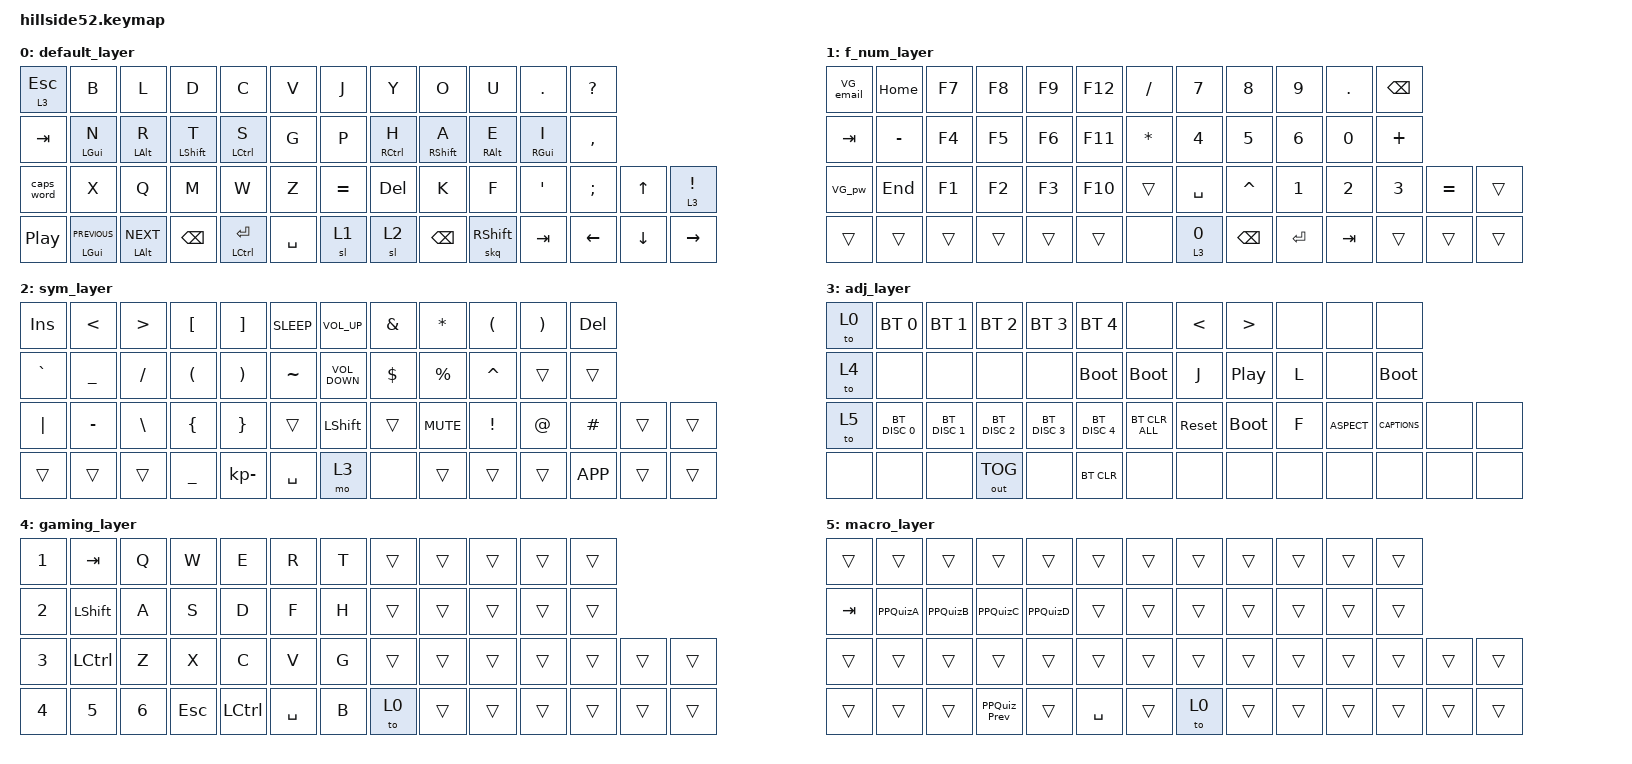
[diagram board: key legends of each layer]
/*
 * Copyright (c) 2021-2022 The ZMK Contributors
 *
 * SPDX-License-Identifier: MIT
 */

#include <behaviors.dtsi>
#include <dt-bindings/zmk/bt.h>
#include <dt-bindings/zmk/keys.h>
#include <dt-bindings/zmk/outputs.h>

/* hillside52.keymap updates */

#define GALLIUM_L  0
#define QWERTY_L   1
#define NUM_L      2
#define NAV_L      3
#define SYM_L      4
#define ADJ_L      5
#define Undo   LC(Z)
#define Cut    LC(X)
#define Copy   LC(C)
#define Paste  LC(V)
#define Redo   LC(Y)

/ {
    behaviors {
        hml: homerow_mods_left {
            compatible = "zmk,behavior-hold-tap";
            #binding-cells = <2>;
            flavor = "tap-preferred";
            tapping-term-ms = <200>;
            quick-tap-ms = <150>;                // Repeat tap within to get the letter
            require-prior-idle-ms = <100>;       // Prevents accidental mods while fast typing
            bindings = <&kp>, <&kp>;

            hold-trigger-key-positions = <6 7 8 9 10 11 18 19 20 21 22 23 31 32 33 34 35 36 37 45 46 47 48 49 50 51>; // Right side + right thumbs
            hold-trigger-on-release;             // Wait for the other key to be released
        };

        hmr: homerow_mods_right {
            compatible = "zmk,behavior-hold-tap";
            #binding-cells = <2>;
            flavor = "tap-preferred";
            tapping-term-ms = <200>;
            quick-tap-ms = <150>;
            require-prior-idle-ms = <100>;
            bindings = <&kp>, <&kp>;

            hold-trigger-key-positions = <0 1 2 3 4 5 12 13 14 15 16 17 24 25 26 27 28 29 30 38 39 40 41 42 43 44>; // Left side + left thumbs
            hold-trigger-on-release;
        };
    };

    skq: skq {
        compatible = "zmk,behavior-sticky-key";
        label = "SK Quick release";
        bindings = <&kp>;
        #binding-cells = <1>;
        quick-release;
        release-after-ms = <2000>;
        ignore-modifiers;
    };

    macros {
        PPQuizA: PPQuizA {
            compatible = "zmk,behavior-macro";
            #binding-cells = <0>;
            bindings = <&kp TAB &kp SPACE &kp TAB &kp TAB &kp SPACE>;
            label = "PPQUIZA";
        };

        PPQuizB: PPQuizB {
            compatible = "zmk,behavior-macro";
            #binding-cells = <0>;
            bindings = <&kp TAB &kp DOWN &kp SPACE &kp TAB &kp TAB &kp SPACE>;
            label = "PPQUIZB";
        };

        PPQuizC: PPQuizC {
            compatible = "zmk,behavior-macro";
            #binding-cells = <0>;
            bindings = <&kp TAB &kp DOWN &kp DOWN &kp SPACE &kp TAB &kp TAB &kp SPACE>;
            label = "PPQUIZC";
        };

        PPQuizD: PPQuizD {
            compatible = "zmk,behavior-macro";
            #binding-cells = <0>;
            bindings = <&kp TAB &kp DOWN &kp DOWN &kp DOWN &kp SPACE &kp TAB &kp TAB &kp SPACE>;
            label = "PPQUIZD";
        };

        PPQuiz_Prev: PPQuiz_Prev {
            compatible = "zmk,behavior-macro";
            #binding-cells = <0>;
            bindings = <&kp TAB &kp TAB &kp SPACE>;
            label = "PPQUIZ_PREV";
        };

        VG_email: VG_email {
            compatible = "zmk,behavior-macro";
            #binding-cells = <0>;
            bindings = <&none &kp S &kp P &kp E &kp N &kp C &kp E &kp R &kp UNDER &kp K &kp N &kp I &kp G &kp H &kp T &kp O &kp N &kp AT &kp V &kp A &kp N &kp G &kp U &kp A &kp R &kp D &kp DOT &kp C &kp O &kp M>;
            label = "VG_EMAIL";
        };

        VG_pw: VG_pw {
            compatible = "zmk,behavior-macro";
            #binding-cells = <0>;
            bindings = <&none &kp LS(S) &kp Y &kp R &kp I &kp N &kp G &kp E &kp N7 &kp B &kp U &kp F &kp F &kp A &kp L &kp O>;
            label = "VG_PW";
        };
    };

    keymap {
        compatible = "zmk,keymap";

        default_layer {
            /* GALLIUM 
 * Efficient column-staggered layout optimized for high alternation.
 */

            bindings = <
&lt 3 ESCAPE      &kp B                    &kp L                &kp D              &kp C                   &kp V      &kp J      &kp Y                 &kp O               &kp U             &kp PERIOD        &kp QUESTION
&kp TAB           &hml LEFT_GUI N          &hml LEFT_ALT R      &hml LEFT_SHIFT T  &hml LEFT_CONTROL S     &kp G      &kp P      &hmr RIGHT_CONTROL H  &hmr RIGHT_SHIFT A  &hmr RIGHT_ALT E  &hmr RIGHT_GUI I  &kp COMMA
&caps_word        &kp X                    &kp Q                &kp M              &kp W                   &kp Z      &kp EQUAL  &kp DELETE            &kp K               &kp F             &kp APOSTROPHE    &kp SEMICOLON  &kp UP    &lt 3 EXCL
&kp C_PLAY_PAUSE  &mt LEFT_GUI C_PREVIOUS  &mt LEFT_ALT C_NEXT  &kp BACKSPACE      &mt LEFT_CONTROL ENTER  &kp SPACE  &sl 1      &sl 2                 &kp BACKSPACE       &skq RIGHT_SHIFT  &kp TAB           &kp LEFT       &kp DOWN  &kp RIGHT
            >;
        };

        f_num_layer {
            /* NUMPAD
 * Left Hand: F-keys mostly
 * Right Hand: Numpad 1-9 on fingers, 0/Enter/. on thumbs
 */

            bindings = <
&VG_email  &kp HOME   &kp F7  &kp F8  &kp F9  &kp F12  &kp SLASH  &kp N7     &kp N8         &kp N9     &kp PERIOD  &kp BSPC
&kp TAB    &kp MINUS  &kp F4  &kp F5  &kp F6  &kp F11  &kp ASTRK  &kp N4     &kp N5         &kp N6     &kp N0      &kp PLUS
&VG_pw     &kp END    &kp F1  &kp F2  &kp F3  &kp F10  &trans     &kp SPACE  &kp CARET      &kp N1     &kp N2      &kp N3    &kp EQUAL  &trans
&trans     &trans     &trans  &trans  &trans  &trans   &none      &lt 3 N0   &kp BACKSPACE  &kp ENTER  &kp TAB     &trans    &trans     &trans
            >;
        };

        sym_layer {
            /* SYM
 */

            bindings = <
&kp INS    &kp LESS_THAN   &kp GREATER_THAN  &kp LEFT_BRACKET      &kp RIGHT_BRACKET      &kp C_SLEEP  &kp C_VOLUME_UP    &kp AMPS    &kp ASTRK    &kp LPAR         &kp RPAR     &kp DEL
&kp GRAVE  &kp UNDERSCORE  &kp SLASH         &kp LEFT_PARENTHESIS  &kp RIGHT_PARENTHESIS  &kp TILDE    &kp C_VOLUME_DOWN  &kp DOLLAR  &kp PERCENT  &kp CARET        &trans       &trans
&kp PIPE   &kp MINUS       &kp BACKSLASH     &kp LEFT_BRACE        &kp RIGHT_BRACE        &trans       &kp LEFT_SHIFT     &trans      &kp C_MUTE   &kp EXCLAMATION  &kp AT_SIGN  &kp POUND  &trans  &trans
&trans     &trans          &trans            &kp UNDERSCORE        &kp KP_SUBTRACT        &kp SPACE    &mo 3              &none       &trans       &trans           &trans       &kp K_APP  &trans  &trans
            >;
        };

        adj_layer {
            /* ADJUST
 */

            bindings = <
&to 0  &bt BT_SEL 0   &bt BT_SEL 1   &bt BT_SEL 2   &bt BT_SEL 3   &bt BT_SEL 4   &none           &kp LESS_THAN  &kp GREATER_THAN  &none  &none         &none
&to 4  &none          &none          &none          &none          &bootloader    &bootloader     &kp J          &kp C_PLAY_PAUSE  &kp L  &none         &bootloader
&to 5  &bt BT_DISC 0  &bt BT_DISC 1  &bt BT_DISC 2  &bt BT_DISC 3  &bt BT_DISC 4  &bt BT_CLR_ALL  &sys_reset     &bootloader       &kp F  &kp C_ASPECT  &kp C_CAPTIONS  &none  &none
&none  &none          &none          &out OUT_TOG   &none          &bt BT_CLR     &none           &none          &none             &none  &none         &none           &none  &none
            >;
        };

        gaming_layer {
            bindings = <
&kp N1  &kp TAB    &kp Q   &kp W       &kp E      &kp R      &kp T  &trans  &trans  &trans  &trans  &trans
&kp N2  &kp LSHFT  &kp A   &kp S       &kp D      &kp F      &kp H  &trans  &trans  &trans  &trans  &trans
&kp N3  &kp LCTRL  &kp Z   &kp X       &kp C      &kp V      &kp G  &trans  &trans  &trans  &trans  &trans  &trans  &trans
&kp N4  &kp N5     &kp N6  &kp ESCAPE  &kp LCTRL  &kp SPACE  &kp B  &to 0   &trans  &trans  &trans  &trans  &trans  &trans
            >;
        };

        macro_layer {
            bindings = <
&trans   &trans    &trans    &trans        &trans    &trans     &trans  &trans  &trans  &trans  &trans  &trans
&kp TAB  &PPQuizA  &PPQuizB  &PPQuizC      &PPQuizD  &trans     &trans  &trans  &trans  &trans  &trans  &trans
&trans   &trans    &trans    &trans        &trans    &trans     &trans  &trans  &trans  &trans  &trans  &trans  &trans  &trans
&trans   &trans    &trans    &PPQuiz_Prev  &trans    &kp SPACE  &trans  &to 0   &trans  &trans  &trans  &trans  &trans  &trans
            >;
        };
    };
};
